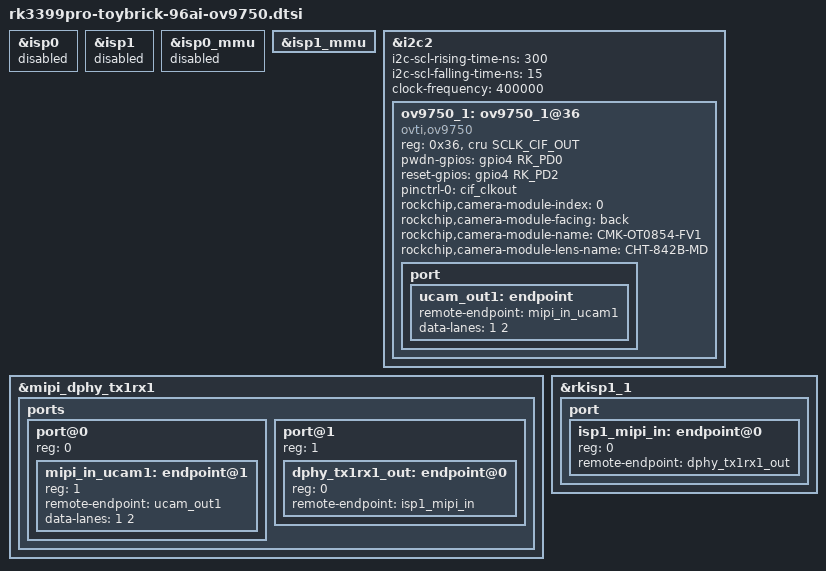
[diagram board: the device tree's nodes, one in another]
/*
 * Copyright (c) 2018 Fuzhou Rockchip Electronics Co., Ltd
 *
 * This file is dual-licensed: you can use it either under the terms
 * of the GPL or the X11 license, at your option. Note that this dual
 * licensing only applies to this file, and not this project as a
 * whole.
 *
 *  a) This file is free software; you can redistribute it and/or
 *     modify it under the terms of the GNU General Public License as
 *     published by the Free Software Foundation; either version 2 of the
 *     License, or (at your option) any later version.
 *
 *     This file is distributed in the hope that it will be useful,
 *     but WITHOUT ANY WARRANTY; without even the implied warranty of
 *     MERCHANTABILITY or FITNESS FOR A PARTICULAR PURPOSE.  See the
 *     GNU General Public License for more details.
 *
 * Or, alternatively,
 *
 *  b) Permission is hereby granted, free of charge, to any person
 *     obtaining a copy of this software and associated documentation
 *     files (the "Software"), to deal in the Software without
 *     restriction, including without limitation the rights to use,
 *     copy, modify, merge, publish, distribute, sublicense, and/or
 *     sell copies of the Software, and to permit persons to whom the
 *     Software is furnished to do so, subject to the following
 *     conditions:
 *
 *     The above copyright notice and this permission notice shall be
 *     included in all copies or substantial portions of the Software.
 *
 *     THE SOFTWARE IS PROVIDED "AS IS", WITHOUT WARRANTY OF ANY KIND,
 *     EXPRESS OR IMPLIED, INCLUDING BUT NOT LIMITED TO THE WARRANTIES
 *     OF MERCHANTABILITY, FITNESS FOR A PARTICULAR PURPOSE AND
 *     NONINFRINGEMENT. IN NO EVENT SHALL THE AUTHORS OR COPYRIGHT
 *     HOLDERS BE LIABLE FOR ANY CLAIM, DAMAGES OR OTHER LIABILITY,
 *     WHETHER IN AN ACTION OF CONTRACT, TORT OR OTHERWISE, ARISING
 *     FROM, OUT OF OR IN CONNECTION WITH THE SOFTWARE OR THE USE OR
 *     OTHER DEALINGS IN THE SOFTWARE.
 */

&isp0 {
	status = "disabled";
};
 
&isp1 {
	status = "disabled";
};

&isp0_mmu {
	status = "disabled";
};

&isp1_mmu {
	status = "okay";
};

&i2c2 {
	status = "okay";
	i2c-scl-rising-time-ns = <300>;
	i2c-scl-falling-time-ns = <15>;
	clock-frequency=<400000>;

	ov9750_1: ov9750_1@36 {//or 0x10 
		compatible = "ovti,ov9750";
		reg = <0x36>
		clocks = <&cru SCLK_CIF_OUT>;
		clock-names = "xvclk";
		pwdn-gpios = <&gpio4 RK_PD0 GPIO_ACTIVE_HIGH>;
		reset-gpios = <&gpio4 RK_PD2 GPIO_ACTIVE_HIGH>;
		pinctrl-names = "default";
		pinctrl-0 = <&cif_clkout>;
		rockchip,camera-module-index = <0>;
		rockchip,camera-module-facing = "back";
		rockchip,camera-module-name = "CMK-OT0854-FV1";
		rockchip,camera-module-lens-name = "CHT-842B-MD";
		port {
			ucam_out1: endpoint {
				remote-endpoint = <&mipi_in_ucam1>;
				data-lanes = <1 2>;
			};
		};
	};
};

&mipi_dphy_tx1rx1 {
	status = "okay";

	ports {
		#address-cells = <1>;
		#size-cells = <0>;

		port@0 {
			reg = <0>;
			#address-cells = <1>;
			#size-cells = <0>;

			mipi_in_ucam1: endpoint@1 {
				reg = <1>;
				remote-endpoint = <&ucam_out1>;
				data-lanes = <1 2>;
			};
		};

		port@1 {
			reg = <1>;
			#address-cells = <1>;
			#size-cells = <0>;

			dphy_tx1rx1_out: endpoint@0 {
				reg = <0>;
				remote-endpoint = <&isp1_mipi_in>;
			};
		};
	};
};

&rkisp1_1 {
	status = "okay";

	port {
		#address-cells = <1>;
		#size-cells = <0>;

		isp1_mipi_in: endpoint@0 {
			reg = <0>;
			remote-endpoint = <&dphy_tx1rx1_out>;
		};
	};
};

